# MB9BF56xR register map
File version: 2.0
CPU: CM4 r0p1, little endian, MPU, FPU, 4 interrupt priority bits
Registers are 32-bit, read-write, reset 0x0 unless marked. A register's access mark holds for its fields unless they carry their own. Offsets are from the block's base; [hi:lo] are bit positions; {n}, {i} and the like mark numbered series; 'fields as' and 'values as' point back to an identical list.

## CAN0 — CAN0 Registers
Base 0x40062000
Same registers: CAN1 0x40063000
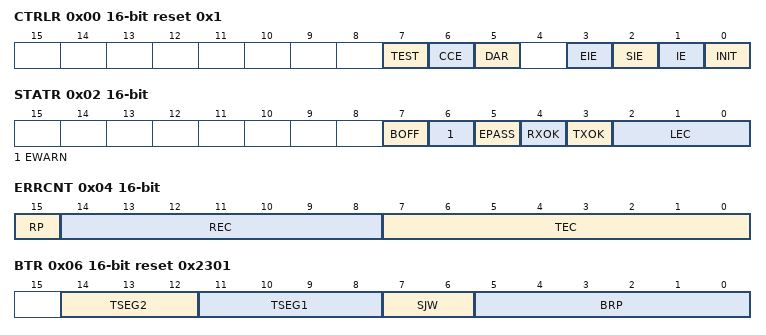
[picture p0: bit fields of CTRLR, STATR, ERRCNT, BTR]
0x00 CTRLR 16-bit reset 0x1 — CAN Control Register
  [7] TEST — Test mode enable bit
  [6] CCE — Bit Timing Register write enable bit
  [5] DAR — Automatic retransmission disable bit
  [3] EIE — Error interrupt code enable bit
  [2] SIE — Status interrupt code enable bit
  [1] IE — Interrupt enable bit
  [0] INIT — Initialization bit
0x02 STATR 16-bit — CAN Status Register
  [7] BOFF ro — Busoff bit
  [6] EWARN ro — Warning bit
  [5] EPASS ro — Error passive bit
  [4] RXOK — Successful message reception bit
  [3] TXOK — Successful message transmission bit
  [2:0] LEC — Last error code bits
0x04 ERRCNT 16-bit ro — CAN Error Counter
  [15] RP — Receive error passive indication
  [14:8] REC — Receive error counter
  [7:0] TEC — Send error counter
0x06 BTR 16-bit reset 0x2301 — CAN Bit Timing Register
  [14:12] TSEG2 — Time segment 2 setting bits
  [11:8] TSEG1 — Time segment 1 setting bits
  [7:6] SJW — Resynchronization jump width setting bits
  [5:0] BRP — Baud rate prescaler setting bits
0x08 INTR 16-bit ro — CAN Interrupt Register
  [15:0] INTID — Interrupt Code
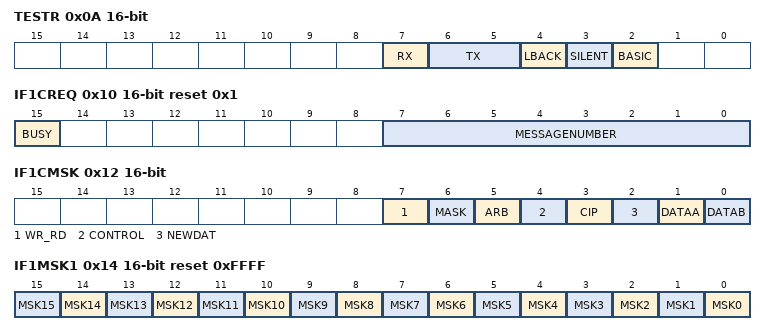
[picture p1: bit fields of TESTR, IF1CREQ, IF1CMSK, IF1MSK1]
0x0A TESTR 16-bit — CAN Test Register
  [7] RX ro — Rx pin monitor bit
  [6:5] TX — TX pin control bit
  [4] LBACK — Loop back mode
  [3] SILENT — Silent mode
  [2] BASIC — Basic mode
0x0C BRPER 16-bit — CAN Prescaler Extension Register
  [3:0] BRPE — Baud rate prescaler extension bit
0x10 IF1CREQ 16-bit reset 0x1 — IF1 Command Request Register
  [15] BUSY — Busy flag bit
  [7:0] MESSAGENUMBER
0x12 IF1CMSK 16-bit — IF1 Command Mask Register
  [7] WR_RD — Writing or reading control bit
  [6] MASK — Mask data update bit
  [5] ARB — Arbitration data update bit
  [4] CONTROL — Control data update bit
  [3] CIP — Interrupt clear bit
  [2] NEWDAT — Message transmission request bit
  [1] DATAA — Data 0-3 update bit
  [0] DATAB — Data 4-7 update bit
0x14 IF1MSK1 16-bit reset 0xFFFF — IF1 Mask Registers 1
  [n] MSK{n} (n=0..15)
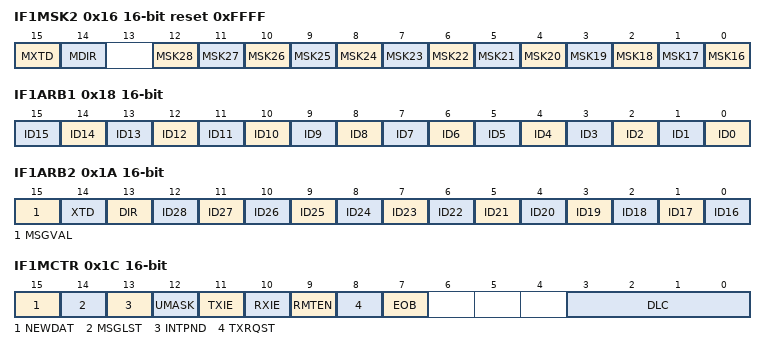
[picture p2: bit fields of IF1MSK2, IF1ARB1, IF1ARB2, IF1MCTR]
0x16 IF1MSK2 16-bit reset 0xFFFF — IF1 Mask Registers 2
  [15] MXTD, [14] MDIR, [n-16] MSK{n} (n=16..28)
0x18 IF1ARB1 16-bit — IF1 Arbitration Registers 1
  [n] ID{n} (n=0..15)
0x1A IF1ARB2 16-bit — IF1 Arbitration Registers 2
  [15] MSGVAL, [14] XTD, [13] DIR, [n-16] ID{n} (n=16..28)
0x1C IF1MCTR 16-bit — IF1 Message Control Register
  [15] NEWDAT, [14] MSGLST, [13] INTPND, [12] UMASK, [11] TXIE, [10] RXIE, [9] RMTEN, [8] TXRQST, [7] EOB, [3:0] DLC
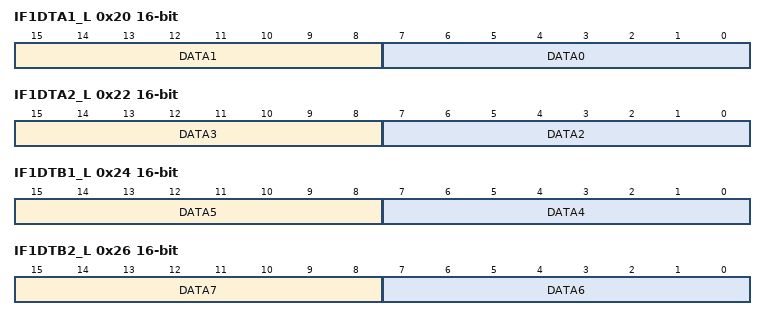
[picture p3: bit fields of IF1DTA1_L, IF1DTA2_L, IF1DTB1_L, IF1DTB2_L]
0x20 IF1DTA1_L 16-bit — IF1 Data Registers A1
  [15:8] DATA1 — Data(1) Little Endian
  [7:0] DATA0 — Data(0) Little Endian
0x22 IF1DTA2_L 16-bit — IF1 Data Registers A2
  [15:8] DATA3 — Data(3) Little Endian
  [7:0] DATA2 — Data(2) Little Endian
0x24 IF1DTB1_L 16-bit — IF1 Data Registers B1
  [15:8] DATA5 — Data(5) Little Endian
  [7:0] DATA4 — Data(4) Little Endian
0x26 IF1DTB2_L 16-bit — IF1 Data Registers B2
  [15:8] DATA7 — Data(7) Little Endian
  [7:0] DATA6 — Data(6) Little Endian
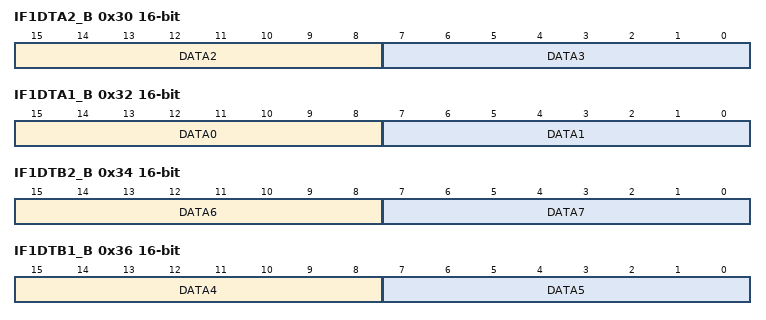
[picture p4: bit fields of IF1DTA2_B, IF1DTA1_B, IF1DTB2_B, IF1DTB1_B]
0x30 IF1DTA2_B 16-bit — IF1 Data Registers A2
  [15:8] DATA2 — Data(2) Big Endian
  [7:0] DATA3 — Data(3) Big Endian
0x32 IF1DTA1_B 16-bit — IF1 Data Registers A1
  [15:8] DATA0 — Data(0) Big Endian
  [7:0] DATA1 — Data(1) Big Endian
0x34 IF1DTB2_B 16-bit — IF1 Data Registers B2
  [15:8] DATA6 — Data(6) Big Endian
  [7:0] DATA7 — Data(7) Big Endian
0x36 IF1DTB1_B 16-bit — IF1 Data Registers B1
  [15:8] DATA4 — Data(4) Big Endian
  [7:0] DATA5 — Data(5) Big Endian
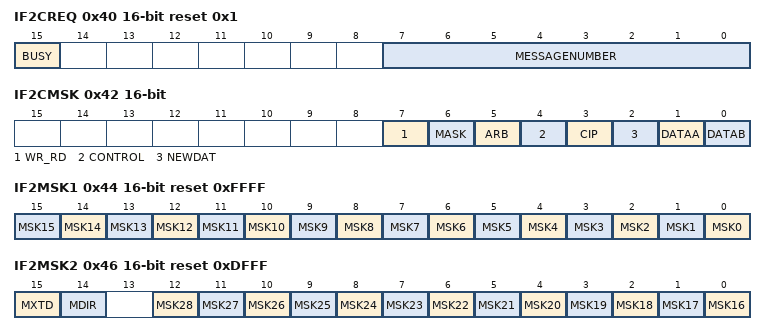
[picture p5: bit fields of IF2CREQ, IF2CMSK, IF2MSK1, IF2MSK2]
0x40 IF2CREQ 16-bit reset 0x1 — IF2 Command Request Register
  [15] BUSY — Busy flag bit
  [7:0] MESSAGENUMBER
0x42 IF2CMSK 16-bit — IF2 Command Mask Register
  fields as IF1CMSK
0x44 IF2MSK1 16-bit reset 0xFFFF — IF2 Mask Registers 1
  [n] MSK{n} (n=0..15)
0x46 IF2MSK2 16-bit reset 0xDFFF — IF2 Mask Registers 2
  [15] MXTD, [14] MDIR, [n-16] MSK{n} (n=16..28)
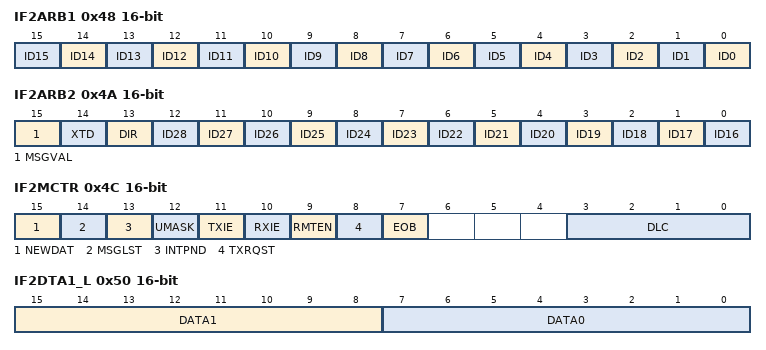
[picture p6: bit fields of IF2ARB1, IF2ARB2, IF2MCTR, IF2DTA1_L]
0x48 IF2ARB1 16-bit — IF2 Arbitration Registers 1
  [n] ID{n} (n=0..15)
0x4A IF2ARB2 16-bit — IF2 Arbitration Registers 2
  [15] MSGVAL, [14] XTD, [13] DIR, [n-16] ID{n} (n=16..28)
0x4C IF2MCTR 16-bit — IF2 Message Control Register
  fields as IF1MCTR
0x50 IF2DTA1_L 16-bit — IF2 Data Registers A1
  fields as IF1DTA1_L
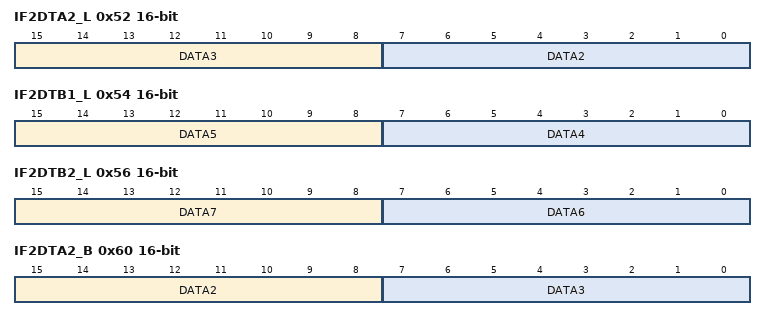
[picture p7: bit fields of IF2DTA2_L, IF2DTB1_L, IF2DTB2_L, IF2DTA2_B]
0x52 IF2DTA2_L 16-bit — IF2 Data Registers A2
  fields as IF1DTA2_L
0x54 IF2DTB1_L 16-bit — IF2 Data Registers B1
  fields as IF1DTB1_L
0x56 IF2DTB2_L 16-bit — IF2 Data Registers B2
  fields as IF1DTB2_L
0x60 IF2DTA2_B 16-bit — IF2 Data Registers A2
  [15:8] DATA2 — Data(2) Big Endian
  [7:0] DATA3 — Data(3) Big Endian
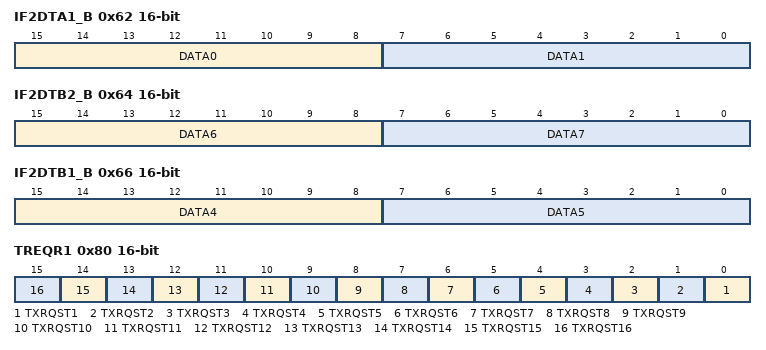
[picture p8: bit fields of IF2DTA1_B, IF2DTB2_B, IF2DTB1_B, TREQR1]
0x62 IF2DTA1_B 16-bit — IF2 Data Registers A1
  [15:8] DATA0 — Data(0) Big Endian
  [7:0] DATA1 — Data(1) Big Endian
0x64 IF2DTB2_B 16-bit — IF2 Data Registers B2
  [15:8] DATA6 — Data(6) Big Endian
  [7:0] DATA7 — Data(7) Big Endian
0x66 IF2DTB1_B 16-bit — IF2 Data Registers B1
  [15:8] DATA4 — Data(4) Big Endian
  [7:0] DATA5 — Data(5) Big Endian
0x80 TREQR1 16-bit ro — CAN Transmit Request Registers 1
  [n-1] TXRQST{n} (n=1..16) — Bit{n-1} of TREQR1
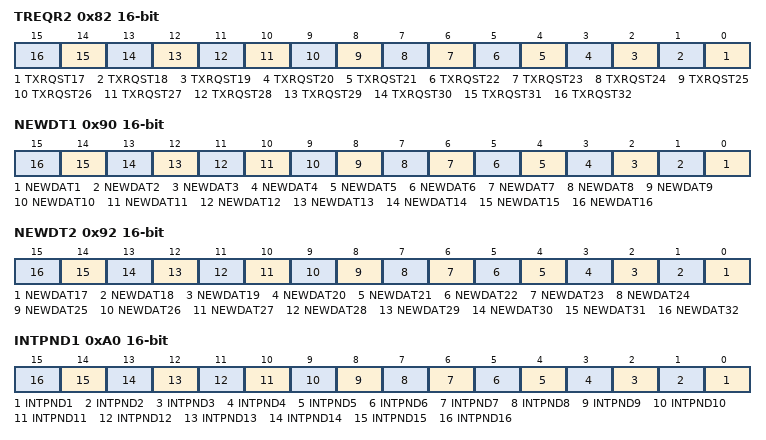
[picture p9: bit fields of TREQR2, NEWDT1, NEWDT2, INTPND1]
0x82 TREQR2 16-bit ro — CAN Transmit Request Registers 2
  [n-17] TXRQST{n} (n=17..32) — Bit{n-17} of TREQR2
0x90 NEWDT1 16-bit ro — CAN New Data Registers 1
  [n-1] NEWDAT{n} (n=1..16) — Bit{n-1} of NEWDT1
0x92 NEWDT2 16-bit ro — CAN New Data Registers 2
  [n-17] NEWDAT{n} (n=17..32) — Bit{n-17} of NEWDT2
0xA0 INTPND1 16-bit ro — CAN Interrupt Pending Registers 1
  [n-1] INTPND{n} (n=1..16) — Bit{n-1} of INTPND1
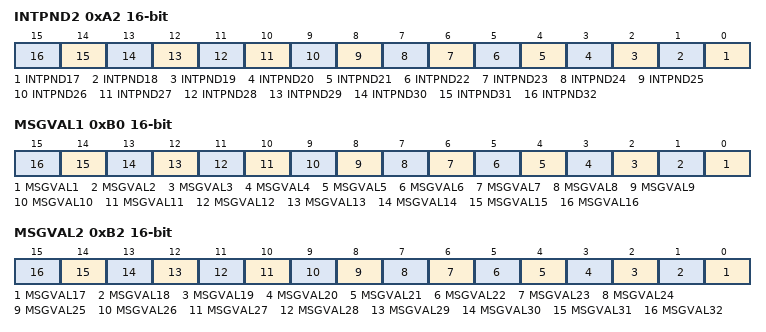
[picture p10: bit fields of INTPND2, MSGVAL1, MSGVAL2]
0xA2 INTPND2 16-bit ro — CAN Interrupt Pending Registers 2
  [n-17] INTPND{n} (n=17..32) — Bit{n-17} of INTPND2
0xB0 MSGVAL1 16-bit ro — CAN Message Valid Registers 1
  [n-1] MSGVAL{n} (n=1..16) — Bit{n-1} of MSGVAL1
0xB2 MSGVAL2 16-bit ro — CAN Message Valid Registers 2
  [n-17] MSGVAL{n} (n=17..32) — Bit{n-17} of MSGVAL2
